# R7FA0E107 register map
Vendor: Renesas Electronics Corporation; Series: RA0; File version: 1.10.00
Arm Cortex,M23 based Microcontroller RA0E1 device
CPU: CM23 r1p0, little endian, no MPU, no FPU, VTOR, 2 interrupt priority bits, 64 interrupts
Registers are 16-bit, read-write, reset 0x0 unless marked. A register's access mark holds for its fields unless they carry their own. Offsets are from the block's base; lines under a group give offsets from that group; [hi:lo] are bit positions; {n}, {i} and the like mark numbered series; 'fields as' and 'values as' point back to an identical list; <NAME> marks a mode.

## Memory map
0x40002000 SRAM blocks up to offset 0x5 — SRAM Control
0x40003000 BUS blocks up to offset 0x1835 — BUS Control
0x40005400 DTC blocks up to offset 0x10 — Data Transfer Controller
0x40006000 ICU blocks up to offset 0x348 — Interrupt Controller
0x4001B000 DBG blocks up to offset 0x14 — Debug Function
0x4001E000 SYSC blocks up to offset 0xC04 — System Control
0x40041000 ELC blocks up to offset 0x34 — Event Link Controller
0x40044400 IWDT blocks up to offset 0x6 — Independent Watchdog Timer
0x40047000 MSTP size 0xC — Module Stop Control
0x40074000 CRC blocks up to offset 0xC — CRC Calculator
0x400A0000 PORT0 blocks up to offset 0xC — Port 0 Control
0x400A0020 PORT1 blocks up to offset 0x10 — Port 1 Control
0x400A0040 PORT2 blocks up to offset 0x10 — Port 2 Control
0x400A0060 PORT3 blocks up to offset 0xC — Port 3 Control
0x400A0080 PORT4 blocks up to offset 0xC — Port 4 Control
0x400A0120 PORT9 blocks up to offset 0xC — Port 9 Control
0x400A0200 PFS_A blocks up to offset 0x141 — Pmn Pin Function Select
0x400A1000 PORGA blocks up to offset 0xA — Product Organize
0x400A1800 ADC_D blocks up to offset 0x128 — A/D Converter
0x400A2000 SAU0 blocks up to offset 0x13A — Serial Array Unit 0
0x400A2200 SAU1 blocks up to offset 0x136 — Serial Array Unit 1
0x400A2600 TAU blocks up to offset 0x140 — Timer Array Unit
0x400A2C00 RTC_C size 0xD — Realtime Clock
0x400A3000 IICA blocks up to offset 0x105 — Serial Interface IICA
0x400A3400 UARTA blocks up to offset 0x101 — Serial Interface UARTA
0x400A3800 TML32 size 0xD — 32-bit Interval Timer
0x400A3B00 PCLBUZ blocks up to offset 0x2 — Clock Output/Buzzer Output Controller
0x400D1000 TRNG blocks up to offset 0x4 — True Random Number Generator
0x407EC000 FLCN blocks up to offset 0x21C — Flash I/O Registers

## Interrupts
{n} IEL{n} (ICU) (n=0..63) — ICU Interrupt {n}

## SRAM — SRAM Control
Base 0x40002000
0x00 PARIOAD 8-bit — SRAM Parity Error Operation After Detection Register
  [0] OAD — Operation After Detection
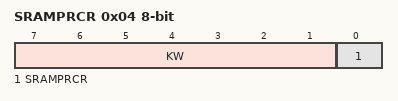
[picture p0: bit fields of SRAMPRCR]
0x04 SRAMPRCR 8-bit — SRAM Protection Register
  [7:1] KW wo — Write Key Code
  [0] SRAMPRCR — Register Write Control

## BUS — BUS Control
Base 0x40003000
0x1008 BUSMCNTSYS — Master Bus Control Register SYS
  [15] IERES — Ignore Error Responses
0x100C BUSMCNTDMA — Master Bus Control Register DMA
  [15] IERES — Ignore Error Responses
0x1820 BUS3ERRADD 32-bit ro reset not defined — Bus Error Address Register 3
  [31:0] BERAD — Bus Error Address
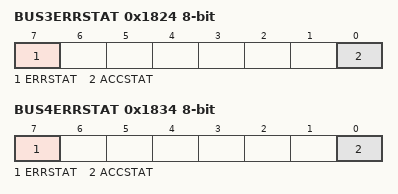
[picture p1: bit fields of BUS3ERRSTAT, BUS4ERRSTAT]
0x1824 BUS3ERRSTAT 8-bit ro (reset mask 0xFE) — BUS Error Status Register 3
  [7] ERRSTAT — Bus Error Status flag
  [0] ACCSTAT — Error Access Status flag
0x1830 BUS4ERRADD 32-bit ro reset not defined — Bus Error Address Register 4
  [31:0] BERAD — Bus Error Address
0x1834 BUS4ERRSTAT 8-bit ro (reset mask 0xFE) — BUS Error Status Register 4
  fields as BUS3ERRSTAT

## Licence text in the file
This software is supplied by Renesas Electronics Corporation and is only intended for use with Renesas products. No other uses are authorized. This software is owned by. Renesas Electronics Corporation and is protected under all applicable laws, including copyright laws. . THIS SOFTWARE IS PROVIDED "AS IS" AND RENESAS MAKES NO WARRANTIES REGARDING. THIS SOFTWARE, WHETHER EXPRESS, IMPLIED OR STATUTORY, INCLUDING BUT NOT LIMITED TO. WARRANTIES OF MERCHANTABILITY, FITNESS FOR A PARTICULAR PURPOSE AND NON-INFRINGEMENT. ALL SUCH WARRANTIES ARE EXPRESSLY DISCLAIMED. TO THE MAXIMUM EXTENT PERMITTED NOT. PROHIBITED BY LAW, NEITHER RENESAS ELECTRONICS CORPORATION NOR ANY OF ITS AFFILIATED. COMPANIES SHALL BE LIABLE FOR ANY DIRECT, INDIRECT, SPECIAL, INCIDENTAL OR CONSEQUENTIAL. DAMAGES FOR ANY REASON RELATED TO THIS SOFTWARE, EVEN IF RENESAS OR ITS AFFILIATES HAVE. BEEN ADVISED OF THE POSSIBILITY OF SUCH DAMAGES. . Renesas reserves the right, without notice, to make changes to this software and to discontinue the availability of this software. By using this software, you agree to the additional terms and conditions found by accessing the following link: http://www.renesas.com/disclaimer
